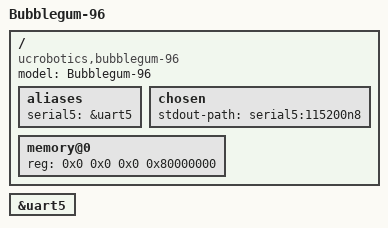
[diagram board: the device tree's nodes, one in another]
// SPDX-License-Identifier: GPL-2.0+
//
// Device Tree Source for Bubblegum-96
//
// Copyright (C) 2015 Actions Semi Co., Ltd.
// Copyright (C) 2018 Manivannan Sadhasivam <manivannan.sadhasivam@linaro.org>

/dts-v1/;
#include "s900.dtsi"

/ {
	model = "Bubblegum-96";
	compatible = "ucrobotics,bubblegum-96", "actions,s900";

	aliases {
		serial5 = &uart5;
	};

	chosen {
		stdout-path = "serial5:115200n8";
	};

	memory@0 {
		device_type = "memory";
		reg = <0x0 0x0 0x0 0x80000000>;
	};
};

&uart5 {
	status = "okay";
};
